AUTOSAR XML (schema 4-0-3)
package /ComponentTypes
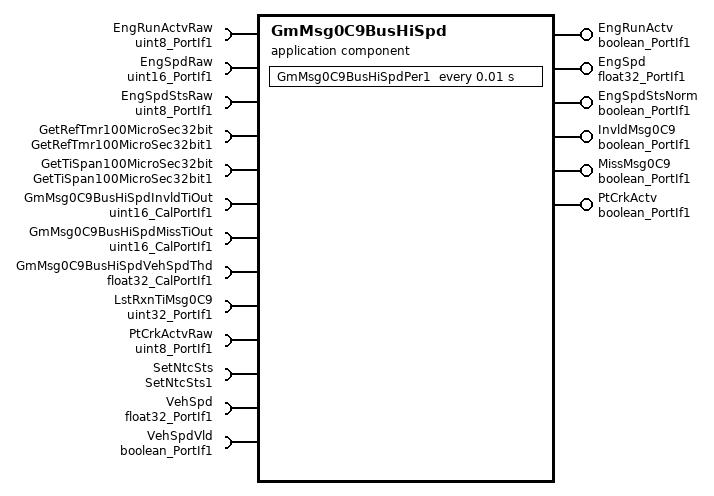
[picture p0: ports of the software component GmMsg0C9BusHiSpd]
  application sw component type GmMsg0C9BusHiSpd
    6 x provide port:
      EngRunActv: nonqueued-sender-com-spec{data-element=Logl, init-value=0}, provided-interface=boolean_PortIf1
      EngSpd: nonqueued-sender-com-spec{data-element=Val, init-value=0}, provided-interface=float32_PortIf1
      EngSpdStsNorm: nonqueued-sender-com-spec{data-element=Logl, init-value=0}, provided-interface=boolean_PortIf1
      InvldMsg0C9: nonqueued-sender-com-spec{data-element=Logl, init-value=0}, provided-interface=boolean_PortIf1
      MissMsg0C9: nonqueued-sender-com-spec{data-element=Logl, init-value=0}, provided-interface=boolean_PortIf1
      PtCrkActv: nonqueued-sender-com-spec{data-element=Logl, init-value=0}, provided-interface=boolean_PortIf1
    13 x require port:
      EngRunActvRaw: nonqueued-receiver-com-spec{data-element=Val, filter=data-filter-type=ALWAYS, init-value=0}, required-interface=uint8_PortIf1
      EngSpdRaw: nonqueued-receiver-com-spec{data-element=Val, filter=data-filter-type=ALWAYS, init-value=0}, required-interface=uint16_PortIf1
      EngSpdStsRaw: nonqueued-receiver-com-spec{data-element=Val, filter=data-filter-type=ALWAYS, init-value=0}, required-interface=uint8_PortIf1
      GetRefTmr100MicroSec32bit: required-interface=GetRefTmr100MicroSec32bit1
      GetTiSpan100MicroSec32bit: required-interface=GetTiSpan100MicroSec32bit1
      GmMsg0C9BusHiSpdInvldTiOut: parameter-require-com-spec{init-value=1000, parameter=Val}, required-interface=uint16_CalPortIf1
      GmMsg0C9BusHiSpdMissTiOut: parameter-require-com-spec{init-value=500, parameter=Val}, required-interface=uint16_CalPortIf1
      GmMsg0C9BusHiSpdVehSpdThd: parameter-require-com-spec{init-value=10, parameter=Val}, required-interface=float32_CalPortIf1
      LstRxnTiMsg0C9: nonqueued-receiver-com-spec{data-element=Val, filter=data-filter-type=ALWAYS, init-value=0}, required-interface=uint32_PortIf1
      PtCrkActvRaw: nonqueued-receiver-com-spec{data-element=Val, filter=data-filter-type=ALWAYS, init-value=0}, required-interface=uint8_PortIf1
      SetNtcSts: required-interface=SetNtcSts1
      VehSpd: nonqueued-receiver-com-spec{data-element=Val, filter=data-filter-type=ALWAYS, init-value=0}, required-interface=float32_PortIf1
      VehSpdVld: nonqueued-receiver-com-spec{data-element=Logl, filter=data-filter-type=ALWAYS, init-value=0}, required-interface=boolean_PortIf1
    behavior GmMsg0C9BusHiSpd_InternalBehavior: data-type-mapping=Nexteer
      ar-typed-per-instance-memorys:
        data GmMsg0C9BusHiSpdInvldMsgTmr: sw-calibration-access=READ-ONLY, type=uint32
        data GmMsg0C9BusHiSpdPrevEndSpd: sw-calibration-access=READ-ONLY, type=float32
        data GmMsg0C9BusHiSpdPrevEngRunActv: sw-calibration-access=READ-ONLY, type=boolean
      timing event TMT_GM0C9HSPer1: start-on-event=GmMsg0C9BusHiSpdPer1, period=0.01
      runnable GmMsg0C9BusHiSpdPer1
        data-receive-point-by-arguments:
          7 x access:
            REC_EngRunActv_Val: accessed-variable=EngRunActvRaw.Val
            REC_EngSpd_Val_1: accessed-variable=EngSpdRaw.Val
            REC_EngSpdSts_Val: accessed-variable=EngSpdStsRaw.Val
            REC_GM3E9HSVehSpd_Val: accessed-variable=VehSpd.Val
            REC_GM3E9HSVehSpdVld_Logl: accessed-variable=VehSpdVld.Logl
            REC_Msg0C9HSLstRxnTi_Val: accessed-variable=LstRxnTiMsg0C9.Val
            REC_PtCrkActv_Val: accessed-variable=PtCrkActvRaw.Val
        data-send-points:
          6 x access:
            SEND_GM0C9HSEngRunActv_Logl: accessed-variable=EngRunActv.Logl
            SEND_GM0C9HSEngSpd_Val: accessed-variable=EngSpd.Val
            SEND_GM0C9HSEngSpdStsNorm_Logl: accessed-variable=EngSpdStsNorm.Logl
            SEND_GM0C9HSMsgInvld_Logl: accessed-variable=InvldMsg0C9.Logl
            SEND_GM0C9HSMsgMiss_Logl: accessed-variable=MissMsg0C9.Logl
            SEND_GM0C9HSPtCrkActv_Logl: accessed-variable=PtCrkActv.Logl
        sync call SC_GetRefTmr100MicroSec32bit_Oper: operation=GetRefTmr100MicroSec32bit.Oper, timeout=0
        sync call SC_GetTiSpan100MicroSec32bit_Oper: operation=GetTiSpan100MicroSec32bit.Oper, timeout=0
        sync call SC_SetNtcSts_Oper: operation=SetNtcSts.Oper, timeout=0
  swc implementation GmMsg0C9BusHiSpd_Implementation: behavior=GmMsg0C9BusHiSpd_InternalBehavior
    code-descriptors:
      code Default: artifact-descriptors=autosar-engineering-object={short-label=Default, category=SWSRC}
